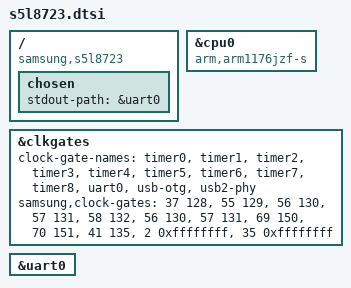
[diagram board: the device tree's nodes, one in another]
// SPDX-License-Identifier: GPL-2.0+ OR MIT
/*
 * Samsung S5L8723 SoC
 *
 * Copyright (C) 2026 The freemyipod team (freemyipod.org)
 */

#include "s5l87xx.dtsi"
#include "s5l8702-common.dtsi"

/ {
	compatible = "samsung,s5l8723", "apple,arm-platform";

	chosen {
		stdout-path = &uart0;
	};
};

&cpu0 {
	compatible = "arm,arm1176jzf-s";
};

&clkgates {
	/*
	 * Clock-gate name -> {gate, bit} table consumed by s5l87xx_enable_clkgate().
	 * Each entry is two cells: gate * 32 + bit, with 0xffffffff for an unused
	 * second gate.
	 */
	clock-gate-names = "timer0", "timer1", "timer2", "timer3", "timer4",
					   "timer5", "timer6", "timer7", "timer8",
					   "uart0", "usb-otg", "usb2-phy";
	samsung,clock-gates = <37 128>, <55 129>, <56 130>, <57 131>, <58 132>,
						  <56 130>, <57 131>, <69 150>, <70 151>,
						  <41 135>, <2 0xffffffff>, <35 0xffffffff>;
};

&uart0 {
	status = "okay";
};
